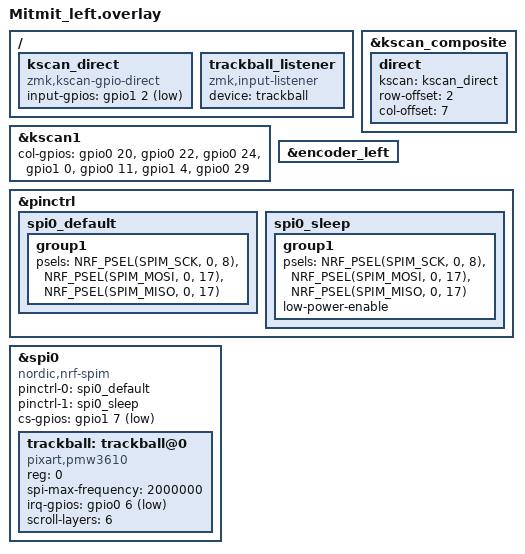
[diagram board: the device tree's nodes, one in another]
#include "Mitmit.dtsi"

/ {
 // Direct GPIO for SW1
	    kscan_direct: kscan_direct {
	        compatible = "zmk,kscan-gpio-direct";
	        input-gpios =                                     // define direct GPIO here...
	            <&gpio1 2 (GPIO_ACTIVE_LOW | GPIO_PULL_UP)>   // Left SW1 (use any free GPIO)
                ;
	        };
  };

&kscan_composite {
        direct {
            kscan = <&kscan_direct>;
	            row-offset = <2>;
	            col-offset = <7>;
             };
	  };

&kscan1 {
    col-gpios
          =  <&gpio0 20 (GPIO_ACTIVE_HIGH | GPIO_PULL_DOWN)>,
             <&gpio0 22 (GPIO_ACTIVE_HIGH | GPIO_PULL_DOWN)>,
             <&gpio0 24 (GPIO_ACTIVE_HIGH | GPIO_PULL_DOWN)>,
             <&gpio1 0  (GPIO_ACTIVE_HIGH | GPIO_PULL_DOWN)>,  
             <&gpio0 11 (GPIO_ACTIVE_HIGH | GPIO_PULL_DOWN)>,
             <&gpio1 4  (GPIO_ACTIVE_HIGH | GPIO_PULL_DOWN)>,
             <&gpio0 29  (GPIO_ACTIVE_HIGH | GPIO_PULL_DOWN)>;
};

&encoder_left {
    status = "okay";
};


&pinctrl {
    spi0_default: spi0_default {
        group1 {
            psels = <NRF_PSEL(SPIM_SCK, 0, 8)>,
                <NRF_PSEL(SPIM_MOSI, 0, 17)>,
                <NRF_PSEL(SPIM_MISO, 0, 17)>;
        };
    };

    spi0_sleep: spi0_sleep {
        group1 {
            psels = <NRF_PSEL(SPIM_SCK, 0, 8)>,
                <NRF_PSEL(SPIM_MOSI, 0, 17)>,
                <NRF_PSEL(SPIM_MISO, 0, 17)>;
            low-power-enable;
        };
    };
};

&spi0 {
    status = "okay";
    compatible = "nordic,nrf-spim";
    pinctrl-0 = <&spi0_default>;
    pinctrl-1 = <&spi0_sleep>;
    pinctrl-names = "default", "sleep";
    cs-gpios = <&gpio1 7 GPIO_ACTIVE_LOW>;

    trackball: trackball@0 {
        status = "okay";
        compatible = "pixart,pmw3610";
        reg = <0>;
        spi-max-frequency = <2000000>;
        irq-gpios = <&gpio0 6 (GPIO_ACTIVE_LOW | GPIO_PULL_UP)>;
         /*   optional features   */
        scroll-layers = <6>;
        // automouse-layer = <5,1>;
        // snipe-layers = <1>;
    };
};

/ {
  trackball_listener {
    compatible = "zmk,input-listener";
    device = <&trackball>;

  };
};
